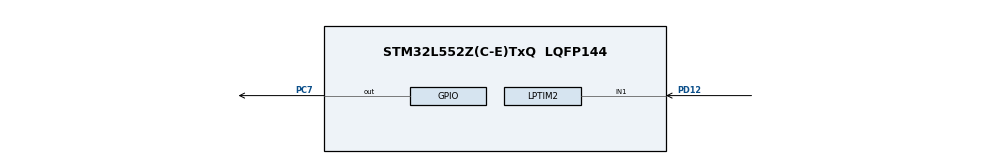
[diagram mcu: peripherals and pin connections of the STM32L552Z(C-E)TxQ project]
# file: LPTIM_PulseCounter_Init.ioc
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Mcu.Family=STM32L5
Mcu.Name=STM32L552Z(C-E)TxQ
Mcu.Package=LQFP144
Mcu.TrustZone=disable
NVIC.LPTIM2_IRQn=true\:0\:0\:false\:false\:true\:true\:true\:true
NVIC.PriorityGroup=NVIC_PRIORITYGROUP_3
PC7.GPIO_ModeDefaultOutputPP=GPIO_MODE_OUTPUT_PP
PC7.GPIO_PuPd=GPIO_PULLUP
PC7.GPIO_Speed=GPIO_SPEED_FREQ_VERY_HIGH
PC7.PinState=GPIO_PIN_SET
PC7.Signal=GPIO_Output
PD12.GPIO_PuPd=GPIO_PULLDOWN
PD12.GPIO_Speed=GPIO_SPEED_FREQ_HIGH
PD12.Mode=Counts_external_clock_with_synchro_01_occur1
PD12.Signal=LPTIM2_IN1
ProjectManager.HeapSize=0x200
ProjectManager.StackSize=0x400
ProjectManager.TargetToolchain=EWARM V8.32
RCC.AHBFreq_Value=110000000
RCC.APB1Freq_Value=110000000
RCC.APB1TimFreq_Value=110000000
RCC.APB2Freq_Value=110000000
RCC.APB2TimFreq_Value=110000000
RCC.CortexFreq_Value=110000000
RCC.HCLKFreq_Value=110000000
RCC.HSE_VALUE=16000000
RCC.HSI48_VALUE=48000000
RCC.HSI_VALUE=16000000
RCC.LPTIM2CLockSelectionVirtual=RCC_LPTIM2CLKSOURCE_LSI
RCC.LSE_VALUE=32768
RCC.MSI_VALUE=4000000
RCC.PLLN=55
RCC.SYSCLKFreq_VALUE=110000000
RCC.SYSCLKSource=RCC_SYSCLKSOURCE_PLLCLK
RCC.VCOOutputFreq_Value=220000000
VP_ICACHE_VS_ICACHE.Mode=DirectMappedCache
VP_PWR_VS_DBSignals.Mode=DisableDeadBatterySignals
board=custom

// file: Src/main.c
/* USER CODE BEGIN Header */
/**
  ******************************************************************************
  * @file           : main.c
  * @brief          : Main program body
  ******************************************************************************
  * @attention
  *
  * Copyright (c) 2019 STMicroelectronics.
  * All rights reserved.
  *
  * This software is licensed under terms that can be found in the LICENSE file
  * in the root directory of this software component.
  * If no LICENSE file comes with this software, it is provided AS-IS.
  *
  ******************************************************************************
  */
/* USER CODE END Header */
#include "main.h"

void SystemClock_Config(void);
static void MX_GPIO_Init(void);
static void MX_ICACHE_Init(void);
static void MX_LPTIM2_Init(void);
/* USER CODE BEGIN PFP */
static void EnterStop1Mode(void);
/* USER CODE END PFP */

int main(void)
{

  /* MCU Configuration--------------------------------------------------------*/

  /* Reset of all peripherals, Initializes the Flash interface and the Systick. */
  LL_APB2_GRP1_EnableClock(LL_APB2_GRP1_PERIPH_SYSCFG);
  LL_APB1_GRP1_EnableClock(LL_APB1_GRP1_PERIPH_PWR);

  /* System interrupt init*/
  NVIC_SetPriorityGrouping(NVIC_PRIORITYGROUP_3);

  /** Disable the internal Pull-Up in Dead Battery pins of UCPD peripheral
  */
  LL_PWR_DisableUCPDDeadBattery();

  /* Configure the system clock */
  SystemClock_Config();

  /* Initialize all configured peripherals */
  MX_GPIO_Init();
  MX_ICACHE_Init();
  MX_LPTIM2_Init();
  /* USER CODE BEGIN 2 */
  /* Enter STOP 1 mode */
  EnterStop1Mode();
  /* USER CODE END 2 */

  /* Infinite loop */
  while (1)
  {

  }
}

void SystemClock_Config(void)
{
  LL_FLASH_SetLatency(LL_FLASH_LATENCY_5);
  while(LL_FLASH_GetLatency()!= LL_FLASH_LATENCY_5)
  {
  }

  LL_PWR_SetRegulVoltageScaling(LL_PWR_REGU_VOLTAGE_SCALE0);
  LL_RCC_LSI_Enable();

   /* Wait till LSI is ready */
  while(LL_RCC_LSI_IsReady() != 1)
  {
  }

  LL_RCC_MSI_Enable();

   /* Wait till MSI is ready */
  while(LL_RCC_MSI_IsReady() != 1)
  {
  }

  LL_RCC_MSI_EnableRangeSelection();
  LL_RCC_MSI_SetRange(LL_RCC_MSIRANGE_6);
  LL_RCC_MSI_SetCalibTrimming(0);
  LL_RCC_PLL_ConfigDomain_SYS(LL_RCC_PLLSOURCE_MSI, LL_RCC_PLLM_DIV_1, 55, LL_RCC_PLLR_DIV_2);
  LL_RCC_PLL_EnableDomain_SYS();
  LL_RCC_PLL_Enable();

   /* Wait till PLL is ready */
  while(LL_RCC_PLL_IsReady() != 1)
  {
  }

   /* Intermediate AHB prescaler 2 when target frequency clock is higher than 80 MHz */
   LL_RCC_SetAHBPrescaler(LL_RCC_SYSCLK_DIV_2);

  LL_RCC_SetSysClkSource(LL_RCC_SYS_CLKSOURCE_PLL);

   /* Wait till System clock is ready */
  while(LL_RCC_GetSysClkSource() != LL_RCC_SYS_CLKSOURCE_STATUS_PLL)
  {
  }

  /* Insure 1us transition state at intermediate medium speed clock*/
  for (__IO uint32_t i = (RCC_MAX_FREQUENCY_MHZ >> 1); i !=0; i--);

  LL_RCC_SetAHBPrescaler(LL_RCC_SYSCLK_DIV_1);
  LL_RCC_SetAPB1Prescaler(LL_RCC_APB1_DIV_1);
  LL_RCC_SetAPB2Prescaler(LL_RCC_APB2_DIV_1);

  LL_Init1msTick(110000000);

  LL_SetSystemCoreClock(110000000);
}

static void MX_ICACHE_Init(void)
{

  /** Enable instruction cache in 1-way (direct mapped cache)
  */
  LL_ICACHE_SetMode(LL_ICACHE_1WAY);
  LL_ICACHE_Enable();

}

static void MX_LPTIM2_Init(void)
{

  LL_GPIO_InitTypeDef GPIO_InitStruct = {0};

  LL_RCC_SetLPTIMClockSource(LL_RCC_LPTIM2_CLKSOURCE_LSI);

  /* Peripheral clock enable */
  LL_APB1_GRP2_EnableClock(LL_APB1_GRP2_PERIPH_LPTIM2);

  LL_AHB2_GRP1_EnableClock(LL_AHB2_GRP1_PERIPH_GPIOD);
  /**LPTIM2 GPIO Configuration
  PD12   ------> LPTIM2_IN1
  */
  GPIO_InitStruct.Pin = LL_GPIO_PIN_12;
  GPIO_InitStruct.Mode = LL_GPIO_MODE_ALTERNATE;
  GPIO_InitStruct.Speed = LL_GPIO_SPEED_FREQ_HIGH;
  GPIO_InitStruct.OutputType = LL_GPIO_OUTPUT_PUSHPULL;
  GPIO_InitStruct.Pull = LL_GPIO_PULL_DOWN;
  GPIO_InitStruct.Alternate = LL_GPIO_AF_14;
  LL_GPIO_Init(GPIOD, &GPIO_InitStruct);

  /* LPTIM2 interrupt Init */
  NVIC_SetPriority(LPTIM2_IRQn, NVIC_EncodePriority(NVIC_GetPriorityGrouping(),0, 0));
  NVIC_EnableIRQ(LPTIM2_IRQn);

  /* USER CODE BEGIN LPTIM2_Init 1 */
  /* Enable the Autoreload match Interrupt */
  LL_LPTIM_EnableIT_ARRM(LPTIM2);
  /* USER CODE END LPTIM2_Init 1 */
  LL_LPTIM_SetClockSource(LPTIM2, LL_LPTIM_CLK_SOURCE_INTERNAL);
  LL_LPTIM_SetPrescaler(LPTIM2, LL_LPTIM_PRESCALER_DIV1);
  LL_LPTIM_SetPolarity(LPTIM2, LL_LPTIM_OUTPUT_POLARITY_REGULAR);
  LL_LPTIM_SetUpdateMode(LPTIM2, LL_LPTIM_UPDATE_MODE_IMMEDIATE);
  LL_LPTIM_SetCounterMode(LPTIM2, LL_LPTIM_COUNTER_MODE_EXTERNAL);
  LL_LPTIM_ConfigClock(LPTIM2, LL_LPTIM_CLK_FILTER_NONE, LL_LPTIM_CLK_POLARITY_RISING);
  LL_LPTIM_TrigSw(LPTIM2);
  LL_LPTIM_SetInput1Src(LPTIM2, LL_LPTIM_INPUT1_SRC_GPIO);
  /* USER CODE BEGIN LPTIM2_Init 2 */

  /* Enable the $MXCONFIG_IP_LPTIMx$ counter */
  LL_LPTIM_Enable(LPTIM2);

  /* Set the Autoreload value */
  LL_LPTIM_SetAutoReload(LPTIM2, 1000);

  /* Start the LPTIM counter in continuous mode */
  LL_LPTIM_StartCounter(LPTIM2, LL_LPTIM_OPERATING_MODE_CONTINUOUS);

  /* USER CODE END LPTIM2_Init 2 */

}

static void MX_GPIO_Init(void)
{
  LL_GPIO_InitTypeDef GPIO_InitStruct = {0};

  /* GPIO Ports Clock Enable */
  LL_AHB2_GRP1_EnableClock(LL_AHB2_GRP1_PERIPH_GPIOD);
  LL_AHB2_GRP1_EnableClock(LL_AHB2_GRP1_PERIPH_GPIOC);

  /**/
  LL_GPIO_SetOutputPin(GPIOC, LL_GPIO_PIN_7);

  /**/
  GPIO_InitStruct.Pin = LL_GPIO_PIN_7;
  GPIO_InitStruct.Mode = LL_GPIO_MODE_OUTPUT;
  GPIO_InitStruct.Speed = LL_GPIO_SPEED_FREQ_VERY_HIGH;
  GPIO_InitStruct.OutputType = LL_GPIO_OUTPUT_PUSHPULL;
  GPIO_InitStruct.Pull = LL_GPIO_PULL_UP;
  LL_GPIO_Init(GPIOC, &GPIO_InitStruct);

}

/* USER CODE BEGIN 4 */
/**
  * @brief  Function to configure and enter in STOP 1 Mode.
  * @param  None
  * @retval None
  */
static void EnterStop1Mode(void)
{
  /* Set low-power mode "Stop" */
  LL_PWR_SetPowerMode(LL_PWR_MODE_STOP1);

  /* Set SLEEPDEEP bit of Cortex System Control Register */
  LL_LPM_EnableDeepSleep();

  /* Request Wait For Interrupt */
  __WFI();
}

/**
  * @brief  LPTimer Autoreload match interrupt processing
  * @param  None
  * @retval None
  */
void LPTimerAutoreloadMatch_Callback(void)
{
  LL_GPIO_TogglePin(GPIOC, LL_GPIO_PIN_7);
}
/* USER CODE END 4 */

void Error_Handler(void)
{
  while (1)
  {
  }
}
